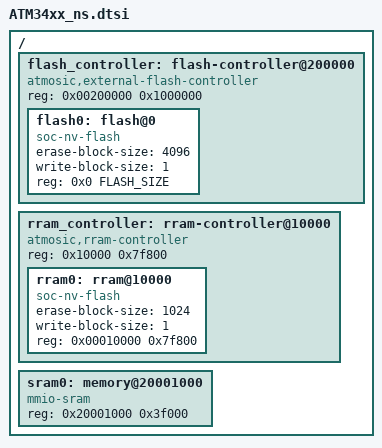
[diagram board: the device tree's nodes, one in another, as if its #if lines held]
/*
 * Copyright (c) 2021-2024 Atmosic
 *
 * SPDX-License-Identifier: Apache-2.0
 */

#include <arm/atmosic/ATM34_ns.dtsi>

#ifndef FLASH_SIZE
#define FLASH_SIZE 0x80000
#endif

/ {
	flash_controller: flash-controller@200000 {
		compatible = "atmosic,external-flash-controller";

		#address-cells = <1>;
		#size-cells = <1>;

		reg = <0x00200000 0x1000000>;
		ranges = <0x0 0x00200000 0x1000000>;

		flash0: flash@0 {
			compatible = "soc-nv-flash";
			erase-block-size = <4096>;
			write-block-size = <1>;
			reg = <0x0 FLASH_SIZE>;
		};
	};

	rram_controller: rram-controller@10000 {
		compatible = "atmosic,rram-controller";

		#address-cells = <1>;
		#size-cells = <1>;

		reg = <0x10000 0x7f800>;

		rram0: rram@10000 {
			compatible = "soc-nv-flash";
			erase-block-size = <1024>;
			write-block-size = <1>;
			reg = <0x00010000 0x7f800>;
		};
	};

#if defined(RUN_IN_FLASH) && (RUN_IN_FLASH == 2)
	sram0: memory@20001000 {
		device_type = "memory";
		compatible = "mmio-sram";
		reg = <0x20001000 0x3f000>;
	};
#else
	sram0: memory@20004000 {
		device_type = "memory";
		compatible = "mmio-sram";
		reg = <0x20004000 0x3c000>;
	};
#endif
};

#include "ATM34xx_partitions.dtsi"
